# ATtiny841 register map
Vendor: Atmel; File version: 1.0
CPU: other r0p0, little endian, no MPU, no FPU, 4 interrupt priority bits
Registers are 8-bit, read-write, reset 0x0 unless marked. A register's access mark holds for its fields unless they carry their own. Offsets are from the block's base; [hi:lo] are bit positions; {n}, {i} and the like mark numbered series.

## TC2 — Timer/Counter, 16-bit
Base 0x00800030
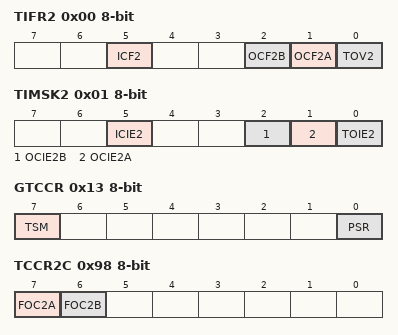
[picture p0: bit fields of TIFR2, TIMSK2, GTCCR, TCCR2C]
0x00 TIFR2 — Timer/Counter Interrupt Flag register (read-only for debugger)
  [5] ICF2 — Timer/Counter2 Input Capture Flag
  [2] OCF2B — Timer/Counter2 Output Compare B Match Flag
  [1] OCF2A — Timer/Counter2 Output Compare A Match Flag
  [0] TOV2 — Timer/Counter2 Overflow Flag
0x01 TIMSK2 — Timer/Counter2 Interrupt Mask Register
  [5] ICIE2 — Timer/Counter2 Input Capture Interrupt Enable
  [2] OCIE2B — Timer/Counter2 Output Compare B Match Interrupt Enable
  [1] OCIE2A — Timer/Counter2 Output Compare A Match Interrupt Enable
  [0] TOIE2 — Timer/Counter2 Overflow Interrupt Enable
0x13 GTCCR — General Timer/Counter Control Register
  [7] TSM — Timer/Counter Synchronization Mode
  [0] PSR — Prescaler Reset Timer/CounterN
0x90 ICR2 16-bit (reset mask 0xFF) — Timer/Counter2 Input Capture Register Bytes
0x92 OCR2B 16-bit (reset mask 0xFF) — Timer/Counter2 Output Compare Register B Bytes
0x94 OCR2A 16-bit (reset mask 0xFF) — Timer/Counter2 Output Compare Register A Bytes
0x96 TCNT2 16-bit (reset mask 0xFF) — Timer/Counter2 Bytes
0x98 TCCR2C — Timer/Counter2 Control Register C (write-only for debugger)
  [7] FOC2A — Force Output Compare for Channel A
  [6] FOC2B — Force Output Compare for Channel B
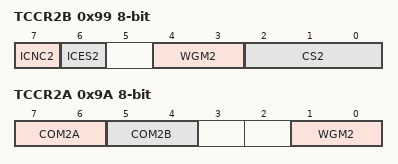
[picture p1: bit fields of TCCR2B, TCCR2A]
0x99 TCCR2B — Timer/Counter2 Control Register B
  [7] ICNC2 — Input Capture 2 Noise Canceler
  [6] ICES2 — Input Capture 2 Edge Select
  [4:3] WGM2 — Waveform Generation Mode Bits
  [2:0] CS2 — Clock Select bits
    0=NO_CLOCK_SOURCE_STOPPED; 1=RUNNING_NO_PRESCALING; 2=RUNNING_CLK_8; 3=RUNNING_CLK_64; 4=RUNNING_CLK_256; 5=RUNNING_CLK_1024; 6=RUNNING_EXTCLK_TN_FALLING_EDGE; 7=RUNNING_EXTCLK_TN_RISING_EDGE
0x9A TCCR2A — Timer/Counter2 Control Register A
  [7:6] COM2A — Compare Output Mode 2A, bits
  [5:4] COM2B — Compare Output Mode 2B, bits
  [1:0] WGM2 — Pulse Width Modulator Select Bits

## TOCPM — Timer/Counter Output Compare Pin
Base 0x00800066
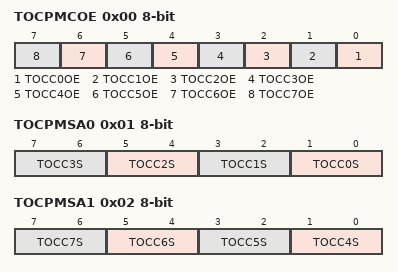
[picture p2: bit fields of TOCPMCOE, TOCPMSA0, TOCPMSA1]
0x00 TOCPMCOE — Timer Output Compare Pin Mux Channel Output Enable
  [n] TOCC{n}OE (n=0..7) — Timer Output Compare Channel {n} Output Enable
0x01 TOCPMSA0 — Timer Output Compare Pin Mux Selection 0
  [2n+1:2n] TOCC{n}S (n=0..3) — Timer Output Compare Channel {n} Selection Bits
0x02 TOCPMSA1 — Timer Output Compare Pin Mux Selection 1
  [2n-7:2n-8] TOCC{n}S (n=4..7) — Timer Output Compare Channel {n} Selection Bits

## TWI — Two Wire Serial Interface
Base 0x008000A0
0x00 TWSD — TWI Slave Data Register (read-only for debugger)
  [7:0] TWSD — TWI slave data bit
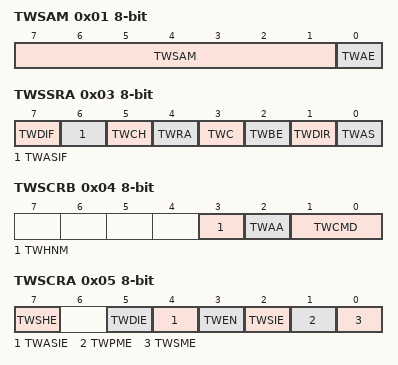
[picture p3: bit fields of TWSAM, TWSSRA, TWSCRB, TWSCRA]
0x01 TWSAM — TWI Slave Address Mask Register
  [7:1] TWSAM — TWI Address Mask Bits
  [0] TWAE — TWI Address Enable
0x02 TWSA — TWI Slave Address Register (read-only for debugger)
0x03 TWSSRA — TWI Slave Status Register A
  [7] TWDIF — TWI Data Interrupt Flag.
  [6] TWASIF — TWI Address/Stop Interrupt Flag
  [5] TWCH — TWI Clock Hold
  [4] TWRA — TWI Receive Acknowledge
  [3] TWC — TWI Collision
  [2] TWBE — TWI Bus Error
  [1] TWDIR — TWI Read/Write Direction
  [0] TWAS — TWI Address or Stop
0x04 TWSCRB — TWI Slave Control Register B
  [3] TWHNM — TWI High Noise Mode
  [2] TWAA — TWI Acknowledge Action
  [1:0] TWCMD
0x05 TWSCRA — TWI Slave Control Register A
  [7] TWSHE — TWI SDA Hold Time Enable
  [5] TWDIE — TWI Data Interrupt Enable
  [4] TWASIE — TWI Address/Stop Interrupt Enable
  [3] TWEN — Two-Wire Interface Enable
  [2] TWSIE — TWI Stop Interrupt Enable
  [1] TWPME — TWI Promiscuous Mode Enable
  [0] TWSME — TWI Smart Mode Enable

## USART0 — USART
Base 0x00800065
0x00 REMAP — Remap Port Pins
  [0] U0MAP — USART0 Pin Mapping
0x1B UDR0 — USART I/O Data Register (write-only for debugger)
0x1C UBRR0 16-bit (reset mask 0xFF) — USART Baud Rate Register Bytes
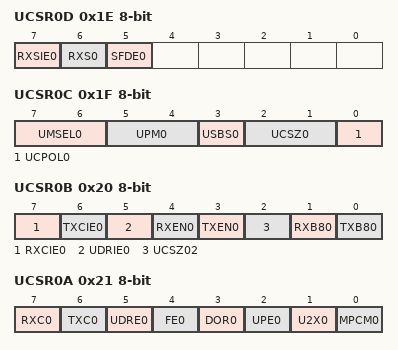
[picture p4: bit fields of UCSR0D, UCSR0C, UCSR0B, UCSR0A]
0x1E UCSR0D — USART Control and Status Register D
  [7] RXSIE0 — USART RX Start Interrupt Enable
  [6] RXS0 — USART RX Start Flag
  [5] SFDE0 — USART RX Start Frame Detection Enable
0x1F UCSR0C — USART Control and Status Register C
  [7:6] UMSEL0 — USART Mode Select
    0=ASYNCHRONOUS_USART; 1=SYNCHRONOUS_USART; 3=MASTER_SPI
  [5:4] UPM0 — Parity Mode Bits
    0=DISABLED; 2=ENABLED_EVEN_PARITY; 3=ENABLED_ODD_PARITY
  [3] USBS0 — Stop Bit Select
    0=1_BIT; 1=2_BIT
  [2:1] UCSZ0 — Character Size
  [0] UCPOL0 — Clock Polarity
0x20 UCSR0B — USART Control and Status Register B
  [7] RXCIE0 — RX Complete Interrupt Enable
  [6] TXCIE0 — TX Complete Interrupt Enable
  [5] UDRIE0 — USART Data register Empty Interrupt Enable
  [4] RXEN0 — Receiver Enable
  [3] TXEN0 — Transmitter Enable
  [2] UCSZ02 — Character Size
  [1] RXB80 — Receive Data Bit 8
  [0] TXB80 — Transmit Data Bit 8
0x21 UCSR0A — USART Control and Status Register A (read-only for debugger)
  [7] RXC0 ro — USART Receive Complete
  [6] TXC0 — USART Transmit Complete
  [5] UDRE0 ro — USART Data Register Empty
  [4] FE0 ro — Framing Error
  [3] DOR0 ro — Data overRun
  [2] UPE0 ro — Parity Error
  [1] U2X0 — Double the USART transmission speed
  [0] MPCM0 — Multi-processor Communication Mode

## USART1 — USART
Base 0x00800090
0x00 UDR1 — USART I/O Data Register (write-only for debugger)
0x01 UBRR1 16-bit (reset mask 0xFF) — USART Baud Rate Register Bytes
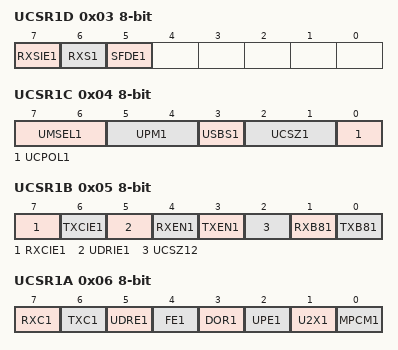
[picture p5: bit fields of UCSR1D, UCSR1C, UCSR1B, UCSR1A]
0x03 UCSR1D — USART Control and Status Register D
  [7] RXSIE1 — USART RX Start Interrupt Enable
  [6] RXS1 — USART RX Start Flag
  [5] SFDE1 — USART RX Start Frame Detection Enable
0x04 UCSR1C — USART Control and Status Register C
  [7:6] UMSEL1 — USART Mode Select
    0=ASYNCHRONOUS_USART; 1=SYNCHRONOUS_USART; 3=MASTER_SPI
  [5:4] UPM1 — Parity Mode Bits
    0=DISABLED; 2=ENABLED_EVEN_PARITY; 3=ENABLED_ODD_PARITY
  [3] USBS1 — Stop Bit Select
    0=1_BIT; 1=2_BIT
  [2:1] UCSZ1 — Character Size
  [0] UCPOL1 — Clock Polarity
0x05 UCSR1B — USART Control and Status Register B
  [7] RXCIE1 — RX Complete Interrupt Enable
  [6] TXCIE1 — TX Complete Interrupt Enable
  [5] UDRIE1 — USART Data register Empty Interrupt Enable
  [4] RXEN1 — Receiver Enable
  [3] TXEN1 — Transmitter Enable
  [2] UCSZ12 — Character Size
  [1] RXB81 — Receive Data Bit 8
  [0] TXB81 — Transmit Data Bit 8
0x06 UCSR1A — USART Control and Status Register A (read-only for debugger)
  [7] RXC1 — USART Receive Complete
  [6] TXC1 — USART Transmit Complete
  [5] UDRE1 — USART Data Register Empty
  [4] FE1 — Framing Error
  [3] DOR1 — Data overRun
  [2] UPE1 — Parity Error
  [1] U2X1 — Double the USART transmission speed
  [0] MPCM1 — Multi-processor Communication Mode

## WDT — Watchdog Timer
Base 0x00800041
0x00 WDTCSR — Watchdog Timer Control and Status Register
  [7] WDIF — Watchdog Timer Interrupt Flag
  [6] WDIE — Watchdog Timer Interrupt Enable
  [3] WDE — Watch Dog Enable
  [5:0] WDP — Watchdog Timer Prescaler Bits
    0=OSCILLATOR_CYCLES_512_16_MS; 1=OSCILLATOR_CYCLES_1K_32_MS; 2=OSCILLATOR_CYCLES_2K_64_MS; 3=OSCILLATOR_CYCLES_4K_0_125_S; 4=OSCILLATOR_CYCLES_8K_0_25_S; 5=OSCILLATOR_CYCLES_16K_0_5_S; 6=OSCILLATOR_CYCLES_32K_1_0_S; 7=OSCILLATOR_CYCLES_64K_2_0_S
